# STM32L5x2 register map
File version: 1.3
Registers are 32-bit, read-write, reset 0x0 unless marked. A register's access mark holds for its fields unless they carry their own. Offsets are from the block's base; [hi:lo] are bit positions; {n}, {i} and the like mark numbered series.

## ICache
Base 0x40030400
Same registers: SEC_ICache 0x50030400
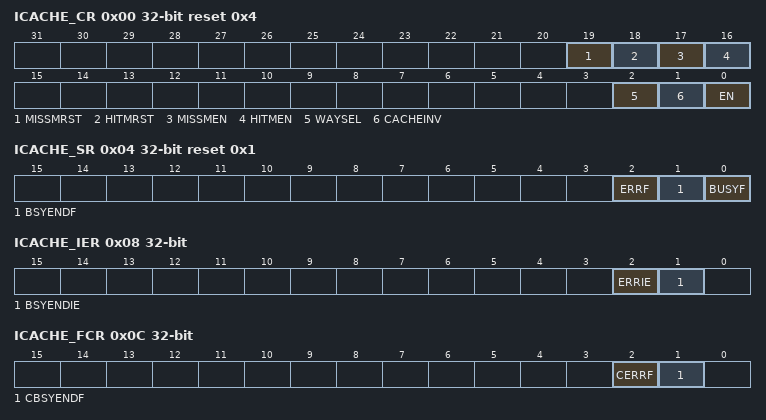
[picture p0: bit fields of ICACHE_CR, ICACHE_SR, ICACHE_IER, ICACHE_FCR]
0x00 ICACHE_CR reset 0x4 — ICACHE control register
  [19] MISSMRST, [18] HITMRST, [17] MISSMEN, [16] HITMEN, [2] WAYSEL, [1] CACHEINV, [0] EN
0x04 ICACHE_SR ro reset 0x1 — ICACHE status register
  [2] ERRF, [1] BSYENDF, [0] BUSYF
0x08 ICACHE_IER — ICACHE interrupt enable register
  [2] ERRIE, [1] BSYENDIE
0x0C ICACHE_FCR wo — ICACHE flag clear register
  [2] CERRF, [1] CBSYENDF
0x10 ICACHE_HMONR ro — ICACHE hit monitor register
  [31:0] HITMON
0x14 ICACHE_MMONR ro — ICACHE miss monitor register
  [15:0] MISSMON
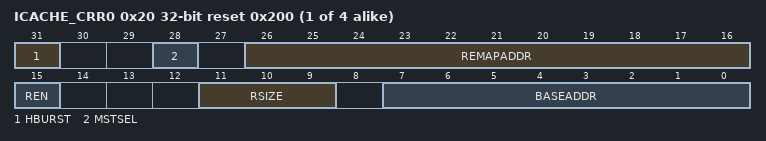
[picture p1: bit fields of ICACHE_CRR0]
{0x20+4i} ICACHE_CRR{i} reset 0x200 (i=0..3) — ICACHE region configuration register
  [31] HBURST, [28] MSTSEL, [26:16] REMAPADDR, [15] REN, [11:9] RSIZE, [7:0] BASEADDR

## IWDG — Independent watchdog
Base 0x40003000
Same registers: SEC_IWDG 0x50003000
0x00 KR wo — Key register
  [15:0] KEY — Key value (write only, read 0x0000)
0x04 PR — Prescaler register
  [2:0] PR — Prescaler divider
0x08 RLR reset 0xFFF — Reload register
  [11:0] RL — Watchdog counter reload value
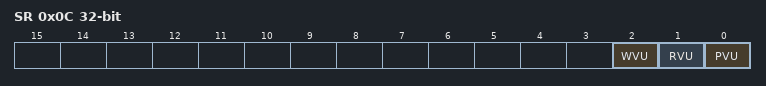
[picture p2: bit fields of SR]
0x0C SR ro — Status register
  [2] WVU — Watchdog counter window value update
  [1] RVU — Watchdog counter reload value update
  [0] PVU — Watchdog prescaler value update
0x10 WINR reset 0xFFF — Window register
  [11:0] WIN — Watchdog counter window value

## LPTIM1 — Low power timer
Base 0x40007C00
Same registers: LPTIM2 0x40009400, LPTIM3 0x40009800, SEC_LPTIM1 0x50007C00, SEC_LPTIM2 0x50009400, SEC_LPTIM3 0x50009800
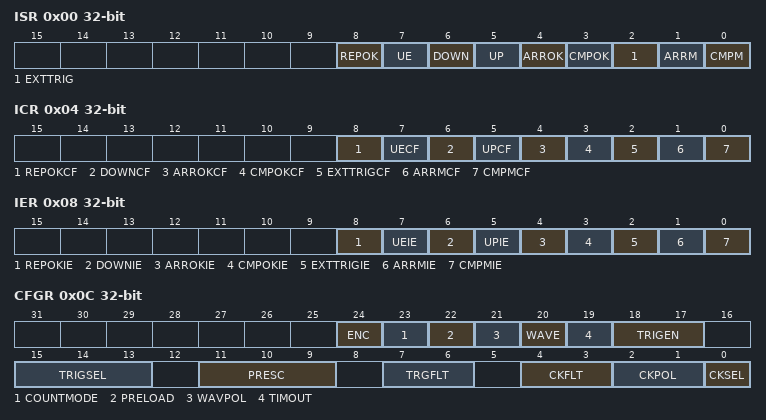
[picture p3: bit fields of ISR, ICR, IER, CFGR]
0x00 ISR ro — Interrupt and Status Register
  [8] REPOK — Repetition register update Ok
  [7] UE — LPTIM update event occurred
  [6] DOWN — Counter direction change up to down
  [5] UP — Counter direction change down to up
  [4] ARROK — Autoreload register update OK
  [3] CMPOK — Compare register update OK
  [2] EXTTRIG — External trigger edge event
  [1] ARRM — Autoreload match
  [0] CMPM — Compare match
0x04 ICR wo — Interrupt Clear Register
  [8] REPOKCF — Repetition register update OK clear flag
  [7] UECF — Update event clear flag
  [6] DOWNCF — Direction change to down Clear Flag
  [5] UPCF — Direction change to UP Clear Flag
  [4] ARROKCF — Autoreload register update OK Clear Flag
  [3] CMPOKCF — Compare register update OK Clear Flag
  [2] EXTTRIGCF — External trigger valid edge Clear Flag
  [1] ARRMCF — Autoreload match Clear Flag
  [0] CMPMCF — compare match Clear Flag
0x08 IER — Interrupt Enable Register
  [8] REPOKIE
  [7] UEIE — Update event interrupt enable
  [6] DOWNIE — Direction change to down Interrupt Enable
  [5] UPIE — Direction change to UP Interrupt Enable
  [4] ARROKIE — Autoreload register update OK Interrupt Enable
  [3] CMPOKIE — Compare register update OK Interrupt Enable
  [2] EXTTRIGIE — External trigger valid edge Interrupt Enable
  [1] ARRMIE — Autoreload match Interrupt Enable
  [0] CMPMIE — Compare match Interrupt Enable
0x0C CFGR — Configuration Register
  [24] ENC — Encoder mode enable
  [23] COUNTMODE — counter mode enabled
  [22] PRELOAD — Registers update mode
  [21] WAVPOL — Waveform shape polarity
  [20] WAVE — Waveform shape
  [19] TIMOUT — Timeout enable
  [18:17] TRIGEN — Trigger enable and polarity
  [15:13] TRIGSEL — Trigger selector
  [11:9] PRESC — Clock prescaler
  [7:6] TRGFLT — Configurable digital filter for trigger
  [4:3] CKFLT — Configurable digital filter for external clock
  [2:1] CKPOL — Clock Polarity
  [0] CKSEL — Clock selector
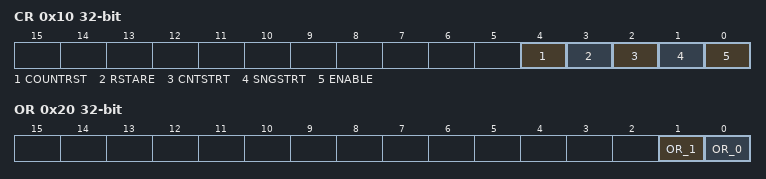
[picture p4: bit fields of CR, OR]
0x10 CR — Control Register
  [4] COUNTRST — Counter reset
  [3] RSTARE — Reset after read enable
  [2] CNTSTRT — Timer start in continuous mode
  [1] SNGSTRT — LPTIM start in single mode
  [0] ENABLE — LPTIM Enable
0x14 CMP — Compare Register
  [15:0] CMP — Compare value
0x18 ARR reset 0x1 — Autoreload Register
  [15:0] ARR — Auto reload value
0x1C CNT ro — Counter Register
  [15:0] CNT — Counter value
0x20 OR — LPTIM option register
  [1] OR_1 — Option register bit 1
  [0] OR_0 — Option register bit 0
0x28 RCR — LPTIM repetition register
  [7:0] REP — Repetition register value
